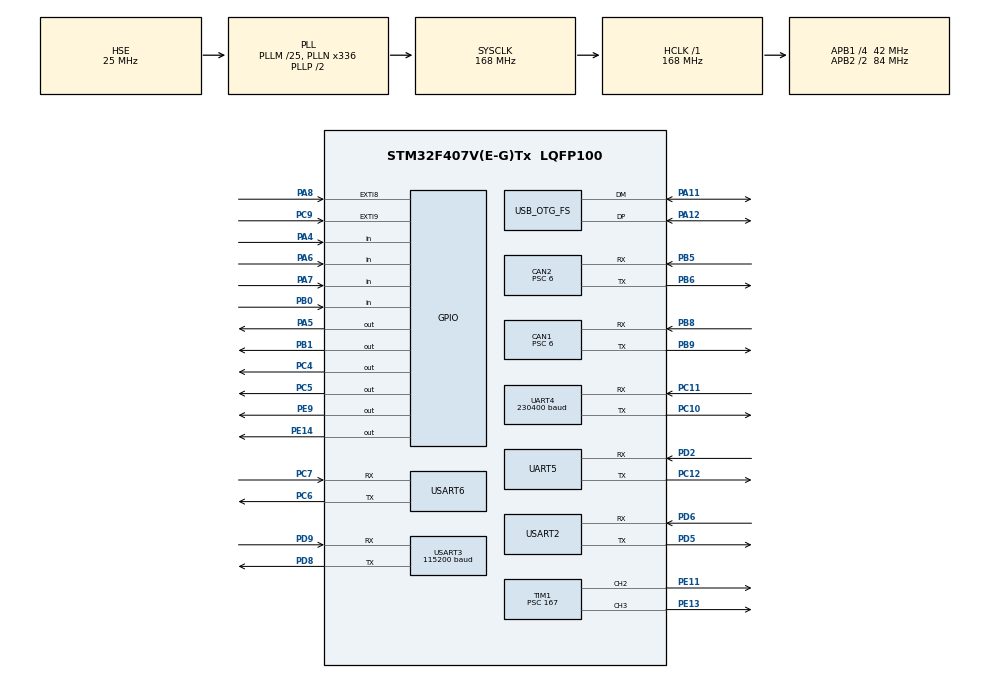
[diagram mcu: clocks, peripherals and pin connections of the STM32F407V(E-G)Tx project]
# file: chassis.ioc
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CAN1.BS1=CAN_BS1_3TQ
CAN1.BS2=CAN_BS2_3TQ
CAN1.CalculateBaudRate=1000000
CAN1.CalculateTimeBit=1000
CAN1.CalculateTimeQuantum=142.85714285714286
CAN1.Prescaler=6
CAN2.BS1=CAN_BS1_3TQ
CAN2.BS2=CAN_BS2_3TQ
CAN2.CalculateBaudRate=1000000
CAN2.CalculateTimeBit=1000
CAN2.CalculateTimeQuantum=142.85714285714286
CAN2.Mode=CAN_MODE_NORMAL
CAN2.Prescaler=6
Dma.Request0=UART4_RX
Dma.Request1=UART4_TX
Dma.Request2=UART5_RX
Dma.Request3=UART5_TX
Dma.Request4=USART3_RX
Dma.Request5=USART3_TX
Dma.Request6=USART2_TX
Dma.Request7=USART2_RX
Dma.Request8=USART6_RX
Dma.Request9=USART6_TX
Dma.UART4_RX.0.Direction=DMA_PERIPH_TO_MEMORY
Dma.UART4_RX.0.FIFOMode=DMA_FIFOMODE_DISABLE
Dma.UART4_RX.0.Instance=DMA1_Stream2
Dma.UART4_RX.0.MemDataAlignment=DMA_MDATAALIGN_BYTE
Dma.UART4_RX.0.MemInc=DMA_MINC_ENABLE
Dma.UART4_RX.0.Mode=DMA_NORMAL
Dma.UART4_RX.0.PeriphDataAlignment=DMA_PDATAALIGN_BYTE
Dma.UART4_RX.0.PeriphInc=DMA_PINC_DISABLE
Dma.UART4_RX.0.Priority=DMA_PRIORITY_LOW
Dma.UART4_TX.1.Direction=DMA_MEMORY_TO_PERIPH
Dma.UART4_TX.1.FIFOMode=DMA_FIFOMODE_DISABLE
Dma.UART4_TX.1.Instance=DMA1_Stream4
Dma.UART4_TX.1.MemDataAlignment=DMA_MDATAALIGN_BYTE
Dma.UART4_TX.1.MemInc=DMA_MINC_ENABLE
Dma.UART4_TX.1.Mode=DMA_NORMAL
Dma.UART4_TX.1.PeriphDataAlignment=DMA_PDATAALIGN_BYTE
Dma.UART4_TX.1.PeriphInc=DMA_PINC_DISABLE
Dma.UART4_TX.1.Priority=DMA_PRIORITY_LOW
Dma.UART5_RX.2.Direction=DMA_PERIPH_TO_MEMORY
Dma.UART5_RX.2.FIFOMode=DMA_FIFOMODE_DISABLE
Dma.UART5_RX.2.Instance=DMA1_Stream0
Dma.UART5_RX.2.MemDataAlignment=DMA_MDATAALIGN_BYTE
Dma.UART5_RX.2.MemInc=DMA_MINC_ENABLE
Dma.UART5_RX.2.Mode=DMA_NORMAL
Dma.UART5_RX.2.PeriphDataAlignment=DMA_PDATAALIGN_BYTE
Dma.UART5_RX.2.PeriphInc=DMA_PINC_DISABLE
Dma.UART5_RX.2.Priority=DMA_PRIORITY_LOW
Dma.UART5_TX.3.Direction=DMA_MEMORY_TO_PERIPH
Dma.UART5_TX.3.FIFOMode=DMA_FIFOMODE_DISABLE
Dma.UART5_TX.3.Instance=DMA1_Stream7
Dma.UART5_TX.3.MemDataAlignment=DMA_MDATAALIGN_BYTE
Dma.UART5_TX.3.MemInc=DMA_MINC_ENABLE
Dma.UART5_TX.3.Mode=DMA_NORMAL
Dma.UART5_TX.3.PeriphDataAlignment=DMA_PDATAALIGN_BYTE
Dma.UART5_TX.3.PeriphInc=DMA_PINC_DISABLE
Dma.UART5_TX.3.Priority=DMA_PRIORITY_LOW
Dma.USART2_RX.7.Direction=DMA_PERIPH_TO_MEMORY
Dma.USART2_RX.7.FIFOMode=DMA_FIFOMODE_DISABLE
Dma.USART2_RX.7.Instance=DMA1_Stream5
Dma.USART2_RX.7.MemDataAlignment=DMA_MDATAALIGN_BYTE
Dma.USART2_RX.7.MemInc=DMA_MINC_ENABLE
Dma.USART2_RX.7.Mode=DMA_NORMAL
Dma.USART2_RX.7.PeriphDataAlignment=DMA_PDATAALIGN_BYTE
Dma.USART2_RX.7.PeriphInc=DMA_PINC_DISABLE
Dma.USART2_RX.7.Priority=DMA_PRIORITY_LOW
Dma.USART2_TX.6.Direction=DMA_MEMORY_TO_PERIPH
Dma.USART2_TX.6.FIFOMode=DMA_FIFOMODE_DISABLE
Dma.USART2_TX.6.Instance=DMA1_Stream6
Dma.USART2_TX.6.MemDataAlignment=DMA_MDATAALIGN_BYTE
Dma.USART2_TX.6.MemInc=DMA_MINC_ENABLE
Dma.USART2_TX.6.Mode=DMA_NORMAL
Dma.USART2_TX.6.PeriphDataAlignment=DMA_PDATAALIGN_BYTE
Dma.USART2_TX.6.PeriphInc=DMA_PINC_DISABLE
Dma.USART2_TX.6.Priority=DMA_PRIORITY_LOW
Dma.USART3_RX.4.Direction=DMA_PERIPH_TO_MEMORY
Dma.USART3_RX.4.FIFOMode=DMA_FIFOMODE_DISABLE
Dma.USART3_RX.4.Instance=DMA1_Stream1
Dma.USART3_RX.4.MemDataAlignment=DMA_MDATAALIGN_BYTE
Dma.USART3_RX.4.MemInc=DMA_MINC_ENABLE
Dma.USART3_RX.4.Mode=DMA_NORMAL
Dma.USART3_RX.4.PeriphDataAlignment=DMA_PDATAALIGN_BYTE
Dma.USART3_RX.4.PeriphInc=DMA_PINC_DISABLE
Dma.USART3_RX.4.Priority=DMA_PRIORITY_LOW
Dma.USART3_TX.5.Direction=DMA_MEMORY_TO_PERIPH
Dma.USART3_TX.5.FIFOMode=DMA_FIFOMODE_DISABLE
Dma.USART3_TX.5.Instance=DMA1_Stream3
Dma.USART3_TX.5.MemDataAlignment=DMA_MDATAALIGN_BYTE
Dma.USART3_TX.5.MemInc=DMA_MINC_ENABLE
Dma.USART3_TX.5.Mode=DMA_NORMAL
Dma.USART3_TX.5.PeriphDataAlignment=DMA_PDATAALIGN_BYTE
Dma.USART3_TX.5.PeriphInc=DMA_PINC_DISABLE
Dma.USART3_TX.5.Priority=DMA_PRIORITY_LOW
Dma.USART6_RX.8.Direction=DMA_PERIPH_TO_MEMORY
Dma.USART6_RX.8.FIFOMode=DMA_FIFOMODE_DISABLE
Dma.USART6_RX.8.Instance=DMA2_Stream1
Dma.USART6_RX.8.MemDataAlignment=DMA_MDATAALIGN_BYTE
Dma.USART6_RX.8.MemInc=DMA_MINC_ENABLE
Dma.USART6_RX.8.Mode=DMA_NORMAL
Dma.USART6_RX.8.PeriphDataAlignment=DMA_PDATAALIGN_BYTE
Dma.USART6_RX.8.PeriphInc=DMA_PINC_DISABLE
Dma.USART6_RX.8.Priority=DMA_PRIORITY_LOW
Dma.USART6_TX.9.Direction=DMA_MEMORY_TO_PERIPH
Dma.USART6_TX.9.FIFOMode=DMA_FIFOMODE_DISABLE
Dma.USART6_TX.9.Instance=DMA2_Stream6
Dma.USART6_TX.9.MemDataAlignment=DMA_MDATAALIGN_BYTE
Dma.USART6_TX.9.MemInc=DMA_MINC_ENABLE
Dma.USART6_TX.9.Mode=DMA_NORMAL
Dma.USART6_TX.9.PeriphDataAlignment=DMA_PDATAALIGN_BYTE
Dma.USART6_TX.9.PeriphInc=DMA_PINC_DISABLE
Dma.USART6_TX.9.Priority=DMA_PRIORITY_LOW
FREERTOS.INCLUDE_uxTaskGetStackHighWaterMark=1
FREERTOS.INCLUDE_vTaskDelayUntil=1
FREERTOS.Tasks01=defaultTask,0,128,StartDefaultTask,Default,NULL,Dynamic,NULL,NULL
FREERTOS.configTOTAL_HEAP_SIZE=40960
FREERTOS.configUSE_TIMERS=1
Mcu.Family=STM32F4
Mcu.Name=STM32F407V(E-G)Tx
Mcu.Package=LQFP100
NVIC.CAN1_RX0_IRQn=true\:5\:0\:false\:false\:true\:true\:true\:true\:true
NVIC.CAN1_TX_IRQn=true\:5\:0\:false\:false\:true\:true\:true\:true\:true
NVIC.CAN2_RX1_IRQn=true\:5\:0\:false\:false\:true\:true\:true\:true\:true
NVIC.CAN2_TX_IRQn=true\:5\:0\:false\:false\:true\:true\:true\:true\:true
NVIC.DMA1_Stream0_IRQn=true\:5\:0\:false\:false\:true\:true\:false\:true\:true
NVIC.DMA1_Stream1_IRQn=true\:5\:0\:false\:false\:true\:true\:false\:true\:true
NVIC.DMA1_Stream2_IRQn=true\:5\:0\:false\:false\:true\:true\:false\:true\:true
NVIC.DMA1_Stream3_IRQn=true\:5\:0\:false\:false\:true\:true\:false\:true\:true
NVIC.DMA1_Stream4_IRQn=true\:5\:0\:false\:false\:true\:true\:false\:true\:true
NVIC.DMA1_Stream5_IRQn=true\:5\:0\:false\:false\:true\:true\:false\:true\:true
NVIC.DMA1_Stream6_IRQn=true\:5\:0\:false\:false\:true\:true\:false\:true\:true
NVIC.DMA1_Stream7_IRQn=true\:5\:0\:false\:false\:true\:true\:false\:true\:true
NVIC.DMA2_Stream1_IRQn=true\:5\:0\:false\:false\:true\:true\:false\:true\:true
NVIC.DMA2_Stream6_IRQn=true\:5\:0\:false\:false\:true\:true\:false\:true\:true
NVIC.EXTI9_5_IRQn=true\:5\:0\:false\:false\:true\:true\:true\:true\:true
NVIC.OTG_FS_IRQn=true\:5\:0\:false\:false\:true\:true\:false\:true\:true
NVIC.PriorityGroup=NVIC_PRIORITYGROUP_4
NVIC.TIM8_TRG_COM_TIM14_IRQn=true\:15\:0\:false\:false\:true\:false\:true\:true\:true
NVIC.TimeBase=TIM8_TRG_COM_TIM14_IRQn
NVIC.TimeBaseIP=TIM14
NVIC.UART4_IRQn=true\:5\:0\:false\:false\:true\:true\:true\:true\:true
NVIC.UART5_IRQn=true\:5\:0\:false\:false\:true\:true\:true\:true\:true
NVIC.USART2_IRQn=true\:5\:0\:false\:false\:true\:true\:true\:true\:true
NVIC.USART3_IRQn=true\:5\:0\:false\:false\:true\:true\:true\:true\:true
NVIC.USART6_IRQn=true\:5\:0\:false\:false\:true\:true\:true\:true\:true
PA11.Mode=Device_Only
PA11.Signal=USB_OTG_FS_DM
PA12.Mode=Device_Only
PA12.Signal=USB_OTG_FS_DP
PA13.Mode=Serial_Wire
PA13.Signal=SYS_JTMS-SWDIO
PA14.Mode=Serial_Wire
PA14.Signal=SYS_JTCK-SWCLK
PA4.GPIO_PuPd=GPIO_PULLDOWN
PA4.Signal=GPIO_Input
PA5.GPIO_PuPd=GPIO_PULLDOWN
PA5.Signal=GPIO_Output
PA6.GPIO_PuPd=GPIO_PULLDOWN
PA6.Signal=GPIO_Input
PA7.GPIO_PuPd=GPIO_PULLDOWN
PA7.Signal=GPIO_Input
PA8.GPIO_ModeDefaultEXTI=GPIO_MODE_IT_RISING_FALLING
PA8.GPIO_PuPd=GPIO_PULLDOWN
PA8.Signal=GPXTI8
PB0.GPIO_PuPd=GPIO_PULLDOWN
PB0.Signal=GPIO_Input
PB1.GPIO_PuPd=GPIO_PULLDOWN
PB1.Signal=GPIO_Output
PB5.Mode=CAN_Activate
PB5.Signal=CAN2_RX
PB6.Mode=CAN_Activate
PB6.Signal=CAN2_TX
PB8.Mode=CAN_Activate
PB8.Signal=CAN1_RX
PB9.Mode=CAN_Activate
PB9.Signal=CAN1_TX
PC10.Mode=Asynchronous
PC10.Signal=UART4_TX
PC11.Mode=Asynchronous
PC11.Signal=UART4_RX
PC12.Mode=Asynchronous
PC12.Signal=UART5_TX
PC4.Signal=GPIO_Output
PC5.Signal=GPIO_Output
PC6.Mode=Asynchronous
PC6.Signal=USART6_TX
PC7.Mode=Asynchronous
PC7.Signal=USART6_RX
PC9.GPIO_ModeDefaultEXTI=GPIO_MODE_IT_RISING_FALLING
PC9.GPIO_PuPd=GPIO_PULLDOWN
PC9.Signal=GPXTI9
PD2.Mode=Asynchronous
PD2.Signal=UART5_RX
PD5.Mode=Asynchronous
PD5.Signal=USART2_TX
PD6.Mode=Asynchronous
PD6.Signal=USART2_RX
PD8.Mode=Asynchronous
PD8.Signal=USART3_TX
PD9.Mode=Asynchronous
PD9.Signal=USART3_RX
PE11.Signal=S_TIM1_CH2
PE13.Signal=S_TIM1_CH3
PE14.GPIO_PuPd=GPIO_PULLDOWN
PE14.Signal=GPIO_Output
PE9.GPIO_PuPd=GPIO_PULLDOWN
PE9.Signal=GPIO_Output
PH0-OSC_IN.Mode=HSE-External-Oscillator
PH0-OSC_IN.Signal=RCC_OSC_IN
PH1-OSC_OUT.Mode=HSE-External-Oscillator
PH1-OSC_OUT.Signal=RCC_OSC_OUT
ProjectManager.HeapSize=0x1000
ProjectManager.StackSize=0x400
ProjectManager.TargetToolchain=MDK-ARM V5
RCC.48MHZClocksFreq_Value=48000000
RCC.AHBFreq_Value=168000000
RCC.APB1CLKDivider=RCC_HCLK_DIV4
RCC.APB1Freq_Value=42000000
RCC.APB1TimFreq_Value=84000000
RCC.APB2CLKDivider=RCC_HCLK_DIV2
RCC.APB2Freq_Value=84000000
RCC.APB2TimFreq_Value=168000000
RCC.CortexFreq_Value=168000000
RCC.HCLKFreq_Value=168000000
RCC.HSE_VALUE=25000000
RCC.HSI_VALUE=16000000
RCC.LSE_VALUE=32768
RCC.PLLM=25
RCC.PLLN=336
RCC.PLLQ=7
RCC.SYSCLKFreq_VALUE=168000000
RCC.SYSCLKSource=RCC_SYSCLKSOURCE_PLLCLK
RCC.VCOOutputFreq_Value=336000000
SH.S_TIM1_CH2.0=TIM1_CH2,PWM Generation2 CH2
SH.S_TIM1_CH3.0=TIM1_CH3,PWM Generation3 CH3
TIM1.Channel-PWM\ Generation2\ CH2=TIM_CHANNEL_2
TIM1.Channel-PWM\ Generation3\ CH3=TIM_CHANNEL_3
TIM1.Period=999
TIM1.Prescaler=167
UART4.BaudRate=230400
UART4.VirtualMode=Asynchronous
UART5.VirtualMode=Asynchronous
USART2.VirtualMode=VM_ASYNC
USART3.BaudRate=115200
USART3.VirtualMode=VM_ASYNC
USART6.VirtualMode=VM_ASYNC
USB_DEVICE.CLASS_NAME_FS=CDC
USB_DEVICE.VirtualMode-CDC_FS=Cdc
USB_DEVICE.VirtualModeFS=Cdc_FS
USB_OTG_FS.VirtualMode=Device_Only
VP_FREERTOS_VS_CMSIS_V1.Mode=CMSIS_V1
VP_SYS_VS_tim14.Mode=TIM14
VP_USB_DEVICE_VS_USB_DEVICE_CDC_FS.Mode=CDC_FS
board=custom

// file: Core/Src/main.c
/* USER CODE BEGIN Header */
/**
  ******************************************************************************
  * @file           : main.c
  * @brief          : Main program body
  ******************************************************************************
  * @attention
  *
  * Copyright (c) 2024 STMicroelectronics.
  * All rights reserved.
  *
  * This software is licensed under terms that can be found in the LICENSE file
  * in the root directory of this software component.
  * If no LICENSE file comes with this software, it is provided AS-IS.
  *
  ******************************************************************************
  */
/* USER CODE END Header */
#include "main.h"
#include "cmsis_os.h"
#include "can.h"
#include "dma.h"
#include "tim.h"
#include "usart.h"
#include "usb_device.h"
#include "gpio.h"

/* USER CODE BEGIN Includes */
#include "RMLibHead.h"
#include "CANDrive.h"
#include "encoder.h"
#include "Task_Init.h"
#include "Task_Init_Main.h"
/* USER CODE END Includes */

void SystemClock_Config(void);
void MX_FREERTOS_Init(void);
/* USER CODE BEGIN PFP */
#define Laser_enable2_Pin GPIO_PIN_3
#define Laser_enable2_GPIO_Port GPIOA
#define Laser_enable1_Pin GPIO_PIN_4
#define Laser_enable1_GPIO_Port GPIOA
#define Laser_enable3_Pin GPIO_PIN_8
#define Laser_enable3_GPIO_Port GPIOA

/* USER CODE END PFP */

int main(void)
{

  /* MCU Configuration--------------------------------------------------------*/

  /* Reset of all peripherals, Initializes the Flash interface and the Systick. */
  HAL_Init();

  /* Configure the system clock */
  SystemClock_Config();

  /* Initialize all configured peripherals */
  MX_GPIO_Init();
  MX_DMA_Init();
  MX_CAN1_Init();
  MX_CAN2_Init();
  MX_UART4_Init();
  MX_UART5_Init();
  MX_USART3_UART_Init();
  MX_USART2_UART_Init();
  MX_USART6_UART_Init();
  MX_TIM1_Init();
  /* USER CODE BEGIN 2 */
	MX_USB_DEVICE_Init();
	Task_Init();
  /* USER CODE END 2 */

  /* Call init function for freertos objects (in cmsis_os2.c) */
  MX_FREERTOS_Init();

  /* Start scheduler */
  osKernelStart();

  /* We should never get here as control is now taken by the scheduler */

  /* Infinite loop */
  while (1)
  {

  }
}

void SystemClock_Config(void)
{
  RCC_OscInitTypeDef RCC_OscInitStruct = {0};
  RCC_ClkInitTypeDef RCC_ClkInitStruct = {0};

  /** Configure the main internal regulator output voltage
  */
  __HAL_RCC_PWR_CLK_ENABLE();
  __HAL_PWR_VOLTAGESCALING_CONFIG(PWR_REGULATOR_VOLTAGE_SCALE1);

  /** Initializes the RCC Oscillators according to the specified parameters
  * in the RCC_OscInitTypeDef structure.
  */
  RCC_OscInitStruct.OscillatorType = RCC_OSCILLATORTYPE_HSE;
  RCC_OscInitStruct.HSEState = RCC_HSE_ON;
  RCC_OscInitStruct.PLL.PLLState = RCC_PLL_ON;
  RCC_OscInitStruct.PLL.PLLSource = RCC_PLLSOURCE_HSE;
  RCC_OscInitStruct.PLL.PLLM = 25;
  RCC_OscInitStruct.PLL.PLLN = 336;
  RCC_OscInitStruct.PLL.PLLP = RCC_PLLP_DIV2;
  RCC_OscInitStruct.PLL.PLLQ = 7;
  if (HAL_RCC_OscConfig(&RCC_OscInitStruct) != HAL_OK)
  {
    Error_Handler();
  }

  /** Initializes the CPU, AHB and APB buses clocks
  */
  RCC_ClkInitStruct.ClockType = RCC_CLOCKTYPE_HCLK|RCC_CLOCKTYPE_SYSCLK
                              |RCC_CLOCKTYPE_PCLK1|RCC_CLOCKTYPE_PCLK2;
  RCC_ClkInitStruct.SYSCLKSource = RCC_SYSCLKSOURCE_PLLCLK;
  RCC_ClkInitStruct.AHBCLKDivider = RCC_SYSCLK_DIV1;
  RCC_ClkInitStruct.APB1CLKDivider = RCC_HCLK_DIV4;
  RCC_ClkInitStruct.APB2CLKDivider = RCC_HCLK_DIV2;

  if (HAL_RCC_ClockConfig(&RCC_ClkInitStruct, FLASH_LATENCY_5) != HAL_OK)
  {
    Error_Handler();
  }
}

void HAL_TIM_PeriodElapsedCallback(TIM_HandleTypeDef *htim)
{
  if (htim->Instance == TIM14)
  {
    HAL_IncTick();
  }
}

void Error_Handler(void)
{
  __disable_irq();
  while (1)
  {
  }
}
